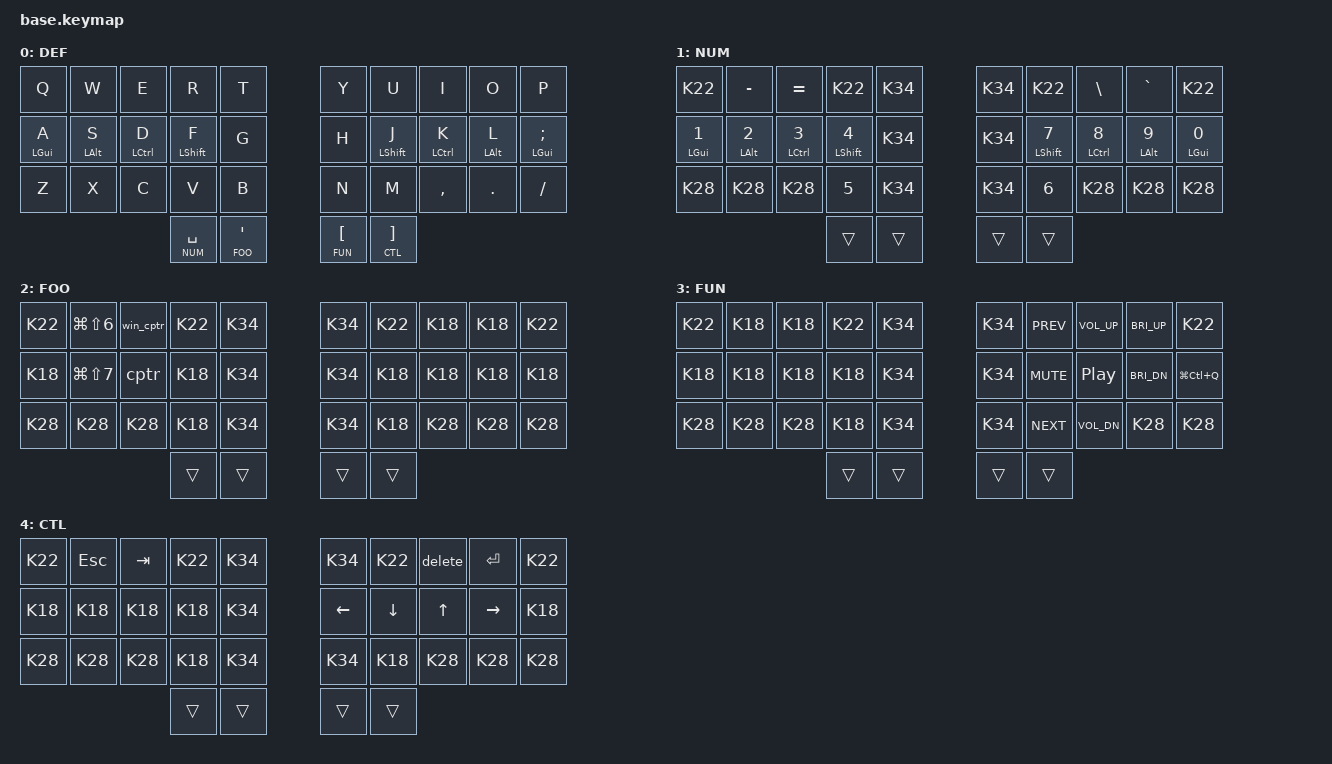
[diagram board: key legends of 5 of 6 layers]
// This file is automatically generated by make_keyboards.sh from config/base.keymap

//╭─────────────╮   ╭─────────────╮   ╭─────────────┬───┬─────────────╮   ╭─────────────╮   ╭─────────────╮                                 ╭─────────────╮   ╭─────────────╮   ╭─────────────┬───┬─────────────╮   ╭─────────────╮   ╭─────────────╮
//     (LT5)         K22 (LT4)         K18 (LT3)         K18 (LT2)         K22 (LT1)         K34 (LT0)                                       K34 (RT0)         K22 (RT1)         K18 (RT2)         K18 (RT3)         K22 (RT4)             (RT5)
//├─────────────┤   ╰─────────────╯   ├─────────────┼───┼─────────────┤   ╰─────────────╯   ├─────────────┤                                 ├─────────────┤   ╰─────────────╯   ├─────────────┼───┼─────────────┤   ╰─────────────╯   ├─────────────┤
//├─────────────┤   ╭─────────────┬───┼─────────────┼───┼─────────────┼───┬─────────────╮   ├─────────────┤                                 ├─────────────┤   ╭─────────────┬───┼─────────────┼───┼─────────────┼───┬─────────────╮   ├─────────────┤
//     (LM5)         K18 (LM4)         K18 (LM3)         K18 (LM2)         K18 (LM1)         K34 (LM0)                                       K34 (RM0)         K18 (RM1)         K18 (RM2)         K18 (RM3)         K18 (RM4)             (RM5)
//├─────────────┤   ╰─────────────┴───┴─────────────┴───┴─────────────┴───┼─────────────┤   ├─────────────┤                                 ├─────────────┤   ├─────────────┼───┴─────────────┴───┴─────────────┴───┴─────────────╯   ├─────────────┤
//├─────────────┤   ╭─────────────┬───┬─────────────┬───┬─────────────╮   ├─────────────┤   ├─────────────┤                                 ├─────────────┤   ├─────────────┤   ╭─────────────┬───┬─────────────┬───┬─────────────╮   ├─────────────┤
//     (LB5)         K28 (LB4)         K28 (LB3)         K28 (LB2)         K18 (LB1)         K34 (LB0)                                       K34 (RB0)         K18 (RB1)         K28 (RB2)         K28 (RB3)         K28 (RB4)             (RB5)
//╰─────────────╯   ╰─────────────┴───┴─────────────┴───┴─────────────╯   ╰─────────────╯   ╰─────────────╯                                 ╰─────────────╯   ╰─────────────╯   ╰─────────────┴───┴─────────────┴───┴─────────────╯   ╰─────────────╯
//                                                                        ╭─────────────┬───┬─────────────╮ ╭─────────────────────────────╮ ╭─────────────┬───┬─────────────╮
//                                                                         K18 (LH2)         K18 (LH1)           (LH0)           (RH0)       K18 (RH1)         K18 (RH2)
//                                                                        ╰─────────────┴───┴─────────────╯ ╰─────────────────────────────╯ ╰─────────────┴───┴─────────────╯

#include <behaviors.dtsi>
#include <dt-bindings/zmk/bt.h>
#include <dt-bindings/zmk/keys.h>

#include "../../../zmk-helpers/helper.h"

//////////////////////////////
// Global Behavior
//////////////////////////////

#define TAP_MS 200

#define MAKE_HRM(                                            \
    NAME ,                                                   \
    HOLD , TAP                                               \
    )                                                        \
    ZMK_BEHAVIOR(                                            \
        NAME,                                                \
        hold_tap,                                            \
        flavor = "balanced";                                 \
        tapping-term-ms = <TAP_MS>;                          \
        quick-tap-ms = <TAP_MS>;                             \
        require-prior-idle-ms = <TAP_MS>;                    \
        bindings = <HOLD>, <TAP>;                            \
    )
MAKE_HRM(hrm, &kp, &kp)

//////////////////////////////
// Layer Definition
//////////////////////////////

#define DEF 0
#define NUM 1
#define FOO 2
#define FUN 3
#define CTL 4
#define BLU 5

//////////////////////////////
// DEF
//////////////////////////////

ZMK_COMBO(comma       , &kp B              , LH1 LH0 , DEF , COMBO_TERM)
ZMK_COMBO(dot         , &kp COMMA          , RH0 RH1 , DEF , COMBO_TERM)

ZMK_LAYER(DEF,
//╭─────────────╮   ╭─────────────╮   ╭─────────────┬───┬─────────────╮   ╭─────────────╮   ╭─────────────╮                                 ╭─────────────╮   ╭─────────────╮   ╭─────────────┬───┬─────────────╮   ╭─────────────╮   ╭─────────────╮
                     &kp Q             &kp W             &kp E             &kp R             &kp T                                           &kp Y             &kp U             &kp I             &kp O             &kp P                
//├─────────────┤   ╰─────────────╯   ├─────────────┼───┼─────────────┤   ╰─────────────╯   ├─────────────┤                                 ├─────────────┤   ╰─────────────╯   ├─────────────┼───┼─────────────┤   ╰─────────────╯   ├─────────────┤
//├─────────────┤   ╭─────────────┬───┼─────────────┼───┼─────────────┼───┬─────────────╮   ├─────────────┤                                 ├─────────────┤   ╭─────────────┬───┼─────────────┼───┼─────────────┼───┬─────────────╮   ├─────────────┤
                     &hrm LGUI  A      &hrm LALT S       &hrm LCTRL D      &hrm LSHFT F      &kp G                                           &kp H             &hrm LSHFT J      &hrm LCTRL K      &hrm LALT L       &hrm LGUI SEMI       
//├─────────────┤   ╰─────────────┴───┴─────────────┴───┴─────────────┴───┼─────────────┤   ├─────────────┤                                 ├─────────────┤   ├─────────────┼───┴─────────────┴───┴─────────────┴───┴─────────────╯   ├─────────────┤
//├─────────────┤   ╭─────────────┬───┬─────────────┬───┬─────────────╮   ├─────────────┤   ├─────────────┤                                 ├─────────────┤   ├─────────────┤   ╭─────────────┬───┬─────────────┬───┬─────────────╮   ├─────────────┤
                     &kp Z             &kp X             &kp C             &kp V             &kp B                                           &kp N             &kp M             &kp COMMA         &kp DOT           &kp FSLH             
//╰─────────────╯   ╰─────────────┴───┴─────────────┴───┴─────────────╯   ╰─────────────╯   ╰─────────────╯                                 ╰─────────────╯   ╰─────────────╯   ╰─────────────┴───┴─────────────┴───┴─────────────╯   ╰─────────────╯
//                                                                        ╭─────────────┬───┬─────────────╮ ╭─────────────────────────────╮ ╭─────────────┬───┬─────────────╮
                                                                           &lt NUM SPACE     &lt FOO APOS                                    &lt FUN LBKT      &lt CTL RBKT
//                                                                        ╰─────────────┴───┴─────────────╯ ╰─────────────────────────────╯ ╰─────────────┴───┴─────────────╯
)

//////////////////////////////
// NUM
//////////////////////////////

ZMK_LAYER(NUM,
//╭─────────────╮   ╭─────────────╮   ╭─────────────┬───┬─────────────╮   ╭─────────────╮   ╭─────────────╮                                 ╭─────────────╮   ╭─────────────╮   ╭─────────────┬───┬─────────────╮   ╭─────────────╮   ╭─────────────╮
                     K22               &kp MINUS         &kp EQUAL         K22               K34                                             K34               K22               &kp BSLH          &kp GRAVE         K22                  
//├─────────────┤   ╰─────────────╯   ├─────────────┼───┼─────────────┤   ╰─────────────╯   ├─────────────┤                                 ├─────────────┤   ╰─────────────╯   ├─────────────┼───┼─────────────┤   ╰─────────────╯   ├─────────────┤
//├─────────────┤   ╭─────────────┬───┼─────────────┼───┼─────────────┼───┬─────────────╮   ├─────────────┤                                 ├─────────────┤   ╭─────────────┬───┼─────────────┼───┼─────────────┼───┬─────────────╮   ├─────────────┤
                     &hrm LGUI N1      &hrm LALT N2      &hrm LCTRL N3     &hrm LSHFT N4     K34                                             K34               &hrm LSHFT N7     &hrm LCTRL N8     &hrm LALT N9      &hrm LGUI N0         
//├─────────────┤   ╰─────────────┴───┴─────────────┴───┴─────────────┴───┼─────────────┤   ├─────────────┤                                 ├─────────────┤   ├─────────────┼───┴─────────────┴───┴─────────────┴───┴─────────────╯   ├─────────────┤
//├─────────────┤   ╭─────────────┬───┬─────────────┬───┬─────────────╮   ├─────────────┤   ├─────────────┤                                 ├─────────────┤   ├─────────────┤   ╭─────────────┬───┬─────────────┬───┬─────────────╮   ├─────────────┤
                     K28               K28               K28               &kp N5            K34                                             K34               &kp N6            K28               K28               K28                  
//╰─────────────╯   ╰─────────────┴───┴─────────────┴───┴─────────────╯   ╰─────────────╯   ╰─────────────╯                                 ╰─────────────╯   ╰─────────────╯   ╰─────────────┴───┴─────────────┴───┴─────────────╯   ╰─────────────╯
//                                                                        ╭─────────────┬───┬─────────────╮ ╭─────────────────────────────╮ ╭─────────────┬───┬─────────────╮
                                                                           &trans            &trans                                          &trans            &trans
//                                                                        ╰─────────────┴───┴─────────────╯ ╰─────────────────────────────╯ ╰─────────────┴───┴─────────────╯
)

//////////////////////////////
// FOO
//////////////////////////////

//                    Capture
// +shift = Scrolling Capture
ZMK_BEHAVIOR(cptr, mod_morph,
    bindings = <&kp LG(LS(N1))>, <&kp LG(LS(N4))>;
    mods = <(MOD_LSFT)>;
)

//             Win Capture
// +shift = Screen Capture
ZMK_BEHAVIOR(win_cptr, mod_morph,
    bindings = <&kp LG(LS(N3))>, <&kp LG(LS(N2))>;
    mods = <(MOD_LSFT)>;
)

#define CPTR     &cptr
#define WIN_CPTR &win_cptr
#define RECORD   &kp LG(LS(N7))
#define OCR      &kp LG(LS(N6))

ZMK_LAYER(FOO,
//╭─────────────╮   ╭─────────────╮   ╭─────────────┬───┬─────────────╮   ╭─────────────╮   ╭─────────────╮                                 ╭─────────────╮   ╭─────────────╮   ╭─────────────┬───┬─────────────╮   ╭─────────────╮   ╭─────────────╮
                     K22               OCR               WIN_CPTR          K22               K34                                             K34               K22               K18               K18               K22                  
//├─────────────┤   ╰─────────────╯   ├─────────────┼───┼─────────────┤   ╰─────────────╯   ├─────────────┤                                 ├─────────────┤   ╰─────────────╯   ├─────────────┼───┼─────────────┤   ╰─────────────╯   ├─────────────┤
//├─────────────┤   ╭─────────────┬───┼─────────────┼───┼─────────────┼───┬─────────────╮   ├─────────────┤                                 ├─────────────┤   ╭─────────────┬───┼─────────────┼───┼─────────────┼───┬─────────────╮   ├─────────────┤
                     K18               RECORD            CPTR              K18               K34                                             K34               K18               K18               K18               K18                  
//├─────────────┤   ╰─────────────┴───┴─────────────┴───┴─────────────┴───┼─────────────┤   ├─────────────┤                                 ├─────────────┤   ├─────────────┼───┴─────────────┴───┴─────────────┴───┴─────────────╯   ├─────────────┤
//├─────────────┤   ╭─────────────┬───┬─────────────┬───┬─────────────╮   ├─────────────┤   ├─────────────┤                                 ├─────────────┤   ├─────────────┤   ╭─────────────┬───┬─────────────┬───┬─────────────╮   ├─────────────┤
                     K28               K28               K28               K18               K34                                             K34               K18               K28               K28               K28                  
//╰─────────────╯   ╰─────────────┴───┴─────────────┴───┴─────────────╯   ╰─────────────╯   ╰─────────────╯                                 ╰─────────────╯   ╰─────────────╯   ╰─────────────┴───┴─────────────┴───┴─────────────╯   ╰─────────────╯
//                                                                        ╭─────────────┬───┬─────────────╮ ╭─────────────────────────────╮ ╭─────────────┬───┬─────────────╮
                                                                           &trans            &trans                                          &trans            &trans
//                                                                        ╰─────────────┴───┴─────────────╯ ╰─────────────────────────────╯ ╰─────────────┴───┴─────────────╯
)

//////////////////////////////
// FUN
//////////////////////////////

ZMK_LAYER(FUN,
//╭─────────────╮   ╭─────────────╮   ╭─────────────┬───┬─────────────╮   ╭─────────────╮   ╭─────────────╮                                 ╭─────────────╮   ╭─────────────╮   ╭─────────────┬───┬─────────────╮   ╭─────────────╮   ╭─────────────╮
                     K22               K18               K18               K22               K34                                             K34               &kp C_PREV        &kp C_VOL_UP      &kp C_BRI_UP      K22                  
//├─────────────┤   ╰─────────────╯   ├─────────────┼───┼─────────────┤   ╰─────────────╯   ├─────────────┤                                 ├─────────────┤   ╰─────────────╯   ├─────────────┼───┼─────────────┤   ╰─────────────╯   ├─────────────┤
//├─────────────┤   ╭─────────────┬───┼─────────────┼───┼─────────────┼───┬─────────────╮   ├─────────────┤                                 ├─────────────┤   ╭─────────────┬───┼─────────────┼───┼─────────────┼───┬─────────────╮   ├─────────────┤
                     K18               K18               K18               K18               K34                                             K34               &kp C_MUTE        &kp C_PP          &kp C_BRI_DN      &kp LG(LC(Q))        
//├─────────────┤   ╰─────────────┴───┴─────────────┴───┴─────────────┴───┼─────────────┤   ├─────────────┤                                 ├─────────────┤   ├─────────────┼───┴─────────────┴───┴─────────────┴───┴─────────────╯   ├─────────────┤
//├─────────────┤   ╭─────────────┬───┬─────────────┬───┬─────────────╮   ├─────────────┤   ├─────────────┤                                 ├─────────────┤   ├─────────────┤   ╭─────────────┬───┬─────────────┬───┬─────────────╮   ├─────────────┤
                     K28               K28               K28               K18               K34                                             K34               &kp C_NEXT        &kp C_VOL_DN      K28               K28                  
//╰─────────────╯   ╰─────────────┴───┴─────────────┴───┴─────────────╯   ╰─────────────╯   ╰─────────────╯                                 ╰─────────────╯   ╰─────────────╯   ╰─────────────┴───┴─────────────┴───┴─────────────╯   ╰─────────────╯
//                                                                        ╭─────────────┬───┬─────────────╮ ╭─────────────────────────────╮ ╭─────────────┬───┬─────────────╮
                                                                           &trans            &trans                                          &trans            &trans
//                                                                        ╰─────────────┴───┴─────────────╯ ╰─────────────────────────────╯ ╰─────────────┴───┴─────────────╯
)

//////////////////////////////
// CTL
//////////////////////////////

ZMK_BEHAVIOR(delete, mod_morph,
    bindings = <&kp BSPC>, <&kp DEL>;
    mods = <(MOD_LSFT)>;
)

ZMK_LAYER(CTL,
//╭─────────────╮   ╭─────────────╮   ╭─────────────┬───┬─────────────╮   ╭─────────────╮   ╭─────────────╮                                 ╭─────────────╮   ╭─────────────╮   ╭─────────────┬───┬─────────────╮   ╭─────────────╮   ╭─────────────╮
                     K22               &kp ESC           &kp TAB           K22               K34                                             K34               K22               &delete           &kp ENTER         K22                  
//├─────────────┤   ╰─────────────╯   ├─────────────┼───┼─────────────┤   ╰─────────────╯   ├─────────────┤                                 ├─────────────┤   ╰─────────────╯   ├─────────────┼───┼─────────────┤   ╰─────────────╯   ├─────────────┤
//├─────────────┤   ╭─────────────┬───┼─────────────┼───┼─────────────┼───┬─────────────╮   ├─────────────┤                                 ├─────────────┤   ╭─────────────┬───┼─────────────┼───┼─────────────┼───┬─────────────╮   ├─────────────┤
                     K18               K18               K18               K18               K34                                             &kp LEFT          &kp DOWN          &kp UP            &kp RIGHT         K18                  
//├─────────────┤   ╰─────────────┴───┴─────────────┴───┴─────────────┴───┼─────────────┤   ├─────────────┤                                 ├─────────────┤   ├─────────────┼───┴─────────────┴───┴─────────────┴───┴─────────────╯   ├─────────────┤
//├─────────────┤   ╭─────────────┬───┬─────────────┬───┬─────────────╮   ├─────────────┤   ├─────────────┤                                 ├─────────────┤   ├─────────────┤   ╭─────────────┬───┬─────────────┬───┬─────────────╮   ├─────────────┤
                     K28               K28               K28               K18               K34                                             K34               K18               K28               K28               K28                  
//╰─────────────╯   ╰─────────────┴───┴─────────────┴───┴─────────────╯   ╰─────────────╯   ╰─────────────╯                                 ╰─────────────╯   ╰─────────────╯   ╰─────────────┴───┴─────────────┴───┴─────────────╯   ╰─────────────╯
//                                                                        ╭─────────────┬───┬─────────────╮ ╭─────────────────────────────╮ ╭─────────────┬───┬─────────────╮
                                                                           &trans            &trans                                          &trans            &trans
//                                                                        ╰─────────────┴───┴─────────────╯ ╰─────────────────────────────╯ ╰─────────────┴───┴─────────────╯
)

//////////////////////////////
// BLU
//////////////////////////////

////////////////////
// combos
////////////////////

ZMK_CONDITIONAL_LAYER(FOO FUN, BLU)

ZMK_LAYER(BLU,
//╭─────────────╮   ╭─────────────╮   ╭─────────────┬───┬─────────────╮   ╭─────────────╮   ╭─────────────╮                                 ╭─────────────╮   ╭─────────────╮   ╭─────────────┬───┬─────────────╮   ╭─────────────╮   ╭─────────────╮
                     K22               &bt BT_CLR        &bootloader       K22               K34                                             K34               K22               &bootloader       &bt BT_CLR        K22                  
//├─────────────┤   ╰─────────────╯   ├─────────────┼───┼─────────────┤   ╰─────────────╯   ├─────────────┤                                 ├─────────────┤   ╰─────────────╯   ├─────────────┼───┼─────────────┤   ╰─────────────╯   ├─────────────┤
//├─────────────┤   ╭─────────────┬───┼─────────────┼───┼─────────────┼───┬─────────────╮   ├─────────────┤                                 ├─────────────┤   ╭─────────────┬───┼─────────────┼───┼─────────────┼───┬─────────────╮   ├─────────────┤
                     &bt BT_SEL 1      &bt BT_SEL 2      &bt BT_SEL 3      &bt BT_SEL 4      K34                                             K34               &bt BT_SEL 7      &bt BT_SEL 8      &bt BT_SEL 9      &bt BT_SEL 0         
//├─────────────┤   ╰─────────────┴───┴─────────────┴───┴─────────────┴───┼─────────────┤   ├─────────────┤                                 ├─────────────┤   ├─────────────┼───┴─────────────┴───┴─────────────┴───┴─────────────╯   ├─────────────┤
//├─────────────┤   ╭─────────────┬───┬─────────────┬───┬─────────────╮   ├─────────────┤   ├─────────────┤                                 ├─────────────┤   ├─────────────┤   ╭─────────────┬───┬─────────────┬───┬─────────────╮   ├─────────────┤
                     &kp N0            K28               K28               &bt BT_SEL 5      K34                                             K34               &bt BT_SEL 6      K28               K28               K28                  
//╰─────────────╯   ╰─────────────┴───┴─────────────┴───┴─────────────╯   ╰─────────────╯   ╰─────────────╯                                 ╰─────────────╯   ╰─────────────╯   ╰─────────────┴───┴─────────────┴───┴─────────────╯   ╰─────────────╯
//                                                                        ╭─────────────┬───┬─────────────╮ ╭─────────────────────────────╮ ╭─────────────┬───┬─────────────╮
                                                                           &trans            &trans                                          &trans            &trans
//                                                                        ╰─────────────┴───┴─────────────╯ ╰─────────────────────────────╯ ╰─────────────┴───┴─────────────╯
)
